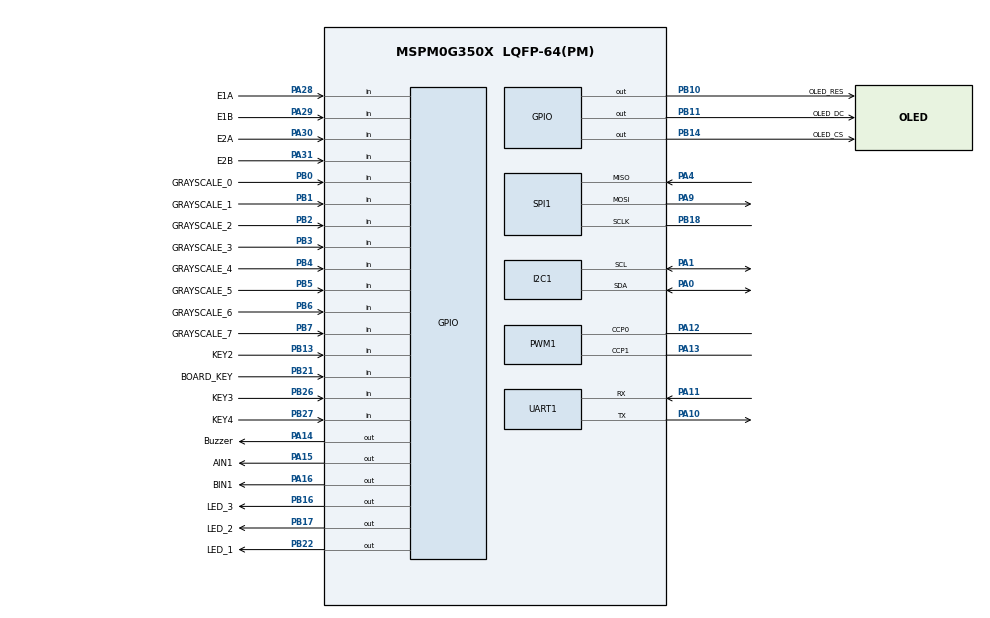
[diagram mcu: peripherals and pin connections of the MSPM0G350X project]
/**
 * @cliArgs --device "MSPM0G350X" --part "Default" --package "LQFP-64(PM)" --product "mspm0_sdk@2.10.00.04"
 * @versions {"tool":"1.26.2+4477"}
 */

/**
 * Import the modules used in this configuration.
 */
const GPIO    = scripting.addModule("/ti/driverlib/GPIO", {}, false);
const GPIO1   = GPIO.addInstance();
const GPIO2   = GPIO.addInstance();
const GPIO3   = GPIO.addInstance();
const GPIO4   = GPIO.addInstance();
const GPIO5   = GPIO.addInstance();
const GPIO6   = GPIO.addInstance();
const GPIO7   = GPIO.addInstance();
const I2C     = scripting.addModule("/ti/driverlib/I2C", {}, false);
const I2C1    = I2C.addInstance();
const PWM     = scripting.addModule("/ti/driverlib/PWM", {}, false);
const PWM1    = PWM.addInstance();
const SPI     = scripting.addModule("/ti/driverlib/SPI", {}, false);
const SPI1    = SPI.addInstance();
const SYSCTL  = scripting.addModule("/ti/driverlib/SYSCTL");
const SYSTICK = scripting.addModule("/ti/driverlib/SYSTICK");
const TIMER   = scripting.addModule("/ti/driverlib/TIMER", {}, false);
const TIMER1  = TIMER.addInstance();
const TIMER2  = TIMER.addInstance();
const UART    = scripting.addModule("/ti/driverlib/UART", {}, false);
const UART1   = UART.addInstance();
const UART2   = UART.addInstance();
const UART3   = UART.addInstance();

/**
 * Write custom configuration values to the imported modules.
 */
const gate7  = system.clockTree["MFCLKGATE"];
gate7.enable = true;

GPIO1.port                          = "PORTB";
GPIO1.$name                         = "LED";
GPIO1.associatedPins.create(3);
GPIO1.associatedPins[0].assignedPin = "22";
GPIO1.associatedPins[0].$name       = "LED_1";
GPIO1.associatedPins[0].pin.$assign = "PB22";
GPIO1.associatedPins[1].$name       = "LED_2";
GPIO1.associatedPins[1].pin.$assign = "PB17";
GPIO1.associatedPins[2].$name       = "LED_3";
GPIO1.associatedPins[2].pin.$assign = "PB16";

const Board = scripting.addModule("/ti/driverlib/Board", {}, false);

GPIO2.port                          = "PORTB";
GPIO2.$name                         = "SPI_OLED";
GPIO2.associatedPins.create(3);
GPIO2.associatedPins[0].assignedPin = "10";
GPIO2.associatedPins[0].ioStructure = "SD";
GPIO2.associatedPins[0].$name       = "OLED_RES";
GPIO2.associatedPins[0].pin.$assign = "PB10";
GPIO2.associatedPins[1].ioStructure = "SD";
GPIO2.associatedPins[1].assignedPin = "11";
GPIO2.associatedPins[1].$name       = "OLED_DC";
GPIO2.associatedPins[1].pin.$assign = "PB11";
GPIO2.associatedPins[2].assignedPin = "14";
GPIO2.associatedPins[2].ioStructure = "SD";
GPIO2.associatedPins[2].$name       = "OLED_CS";
GPIO2.associatedPins[2].pin.$assign = "PB14";

GPIO3.$name                              = "KEY_GROIP";
GPIO3.associatedPins.create(5);
GPIO3.associatedPins[0].$name            = "BOARD_KEY";
GPIO3.associatedPins[0].direction        = "INPUT";
GPIO3.associatedPins[0].assignedPort     = "PORTB";
GPIO3.associatedPins[0].assignedPin      = "21";
GPIO3.associatedPins[0].internalResistor = "PULL_UP";
GPIO3.associatedPins[0].pin.$assign      = "PB21";
GPIO3.associatedPins[1].$name            = "KEY1";
GPIO3.associatedPins[1].direction        = "INPUT";
GPIO3.associatedPins[1].internalResistor = "PULL_UP";
GPIO3.associatedPins[2].$name            = "KEY2";
GPIO3.associatedPins[2].direction        = "INPUT";
GPIO3.associatedPins[2].internalResistor = "PULL_UP";
GPIO3.associatedPins[2].pin.$assign      = "PB13";
GPIO3.associatedPins[3].$name            = "KEY3";
GPIO3.associatedPins[3].direction        = "INPUT";
GPIO3.associatedPins[3].internalResistor = "PULL_UP";
GPIO3.associatedPins[3].pin.$assign      = "PB26";
GPIO3.associatedPins[4].$name            = "KEY4";
GPIO3.associatedPins[4].direction        = "INPUT";
GPIO3.associatedPins[4].internalResistor = "PULL_UP";
GPIO3.associatedPins[4].pin.$assign      = "PB27";

GPIO4.port                                = "PORTA";
GPIO4.$name                               = "ENCODER";
GPIO4.associatedPins.create(4);
GPIO4.associatedPins[0].$name             = "E1A";
GPIO4.associatedPins[0].direction         = "INPUT";
GPIO4.associatedPins[0].assignedPin       = "28";
GPIO4.associatedPins[0].interruptEn       = true;
GPIO4.associatedPins[0].inputFilter       = "8_CYCLES";
GPIO4.associatedPins[0].internalResistor  = "PULL_DOWN";
GPIO4.associatedPins[0].polarity          = "RISE_FALL";
GPIO4.associatedPins[0].interruptPriority = "0";
GPIO4.associatedPins[0].pin.$assign       = "PA28";
GPIO4.associatedPins[1].$name             = "E1B";
GPIO4.associatedPins[1].direction         = "INPUT";
GPIO4.associatedPins[1].assignedPin       = "29";
GPIO4.associatedPins[1].interruptEn       = true;
GPIO4.associatedPins[1].internalResistor  = "PULL_DOWN";
GPIO4.associatedPins[1].inputFilter       = "8_CYCLES";
GPIO4.associatedPins[1].polarity          = "RISE_FALL";
GPIO4.associatedPins[1].interruptPriority = "0";
GPIO4.associatedPins[1].pin.$assign       = "PA29";
GPIO4.associatedPins[2].$name             = "E2A";
GPIO4.associatedPins[2].direction         = "INPUT";
GPIO4.associatedPins[2].assignedPin       = "30";
GPIO4.associatedPins[2].interruptEn       = true;
GPIO4.associatedPins[2].internalResistor  = "PULL_DOWN";
GPIO4.associatedPins[2].inputFilter       = "8_CYCLES";
GPIO4.associatedPins[2].polarity          = "RISE_FALL";
GPIO4.associatedPins[2].interruptPriority = "0";
GPIO4.associatedPins[2].pin.$assign       = "PA30";
GPIO4.associatedPins[3].$name             = "E2B";
GPIO4.associatedPins[3].direction         = "INPUT";
GPIO4.associatedPins[3].assignedPin       = "31";
GPIO4.associatedPins[3].interruptEn       = true;
GPIO4.associatedPins[3].internalResistor  = "PULL_DOWN";
GPIO4.associatedPins[3].inputFilter       = "8_CYCLES";
GPIO4.associatedPins[3].polarity          = "RISE_FALL";
GPIO4.associatedPins[3].interruptPriority = "0";
GPIO4.associatedPins[3].pin.$assign       = "PA31";

GPIO5.$name                         = "A4950";
GPIO5.associatedPins.create(2);
GPIO5.associatedPins[0].$name       = "AIN1";
GPIO5.associatedPins[0].pin.$assign = "PA15";
GPIO5.associatedPins[1].$name       = "BIN1";
GPIO5.associatedPins[1].pin.$assign = "PA16";

GPIO6.$name                         = "GRAYSCALE";
GPIO6.associatedPins.create(8);
GPIO6.associatedPins[0].$name       = "GRAYSCALE_0";
GPIO6.associatedPins[0].direction   = "INPUT";
GPIO6.associatedPins[0].pin.$assign = "PB0";
GPIO6.associatedPins[1].$name       = "GRAYSCALE_1";
GPIO6.associatedPins[1].direction   = "INPUT";
GPIO6.associatedPins[1].pin.$assign = "PB1";
GPIO6.associatedPins[2].$name       = "GRAYSCALE_2";
GPIO6.associatedPins[2].direction   = "INPUT";
GPIO6.associatedPins[2].pin.$assign = "PB2";
GPIO6.associatedPins[3].$name       = "GRAYSCALE_3";
GPIO6.associatedPins[3].direction   = "INPUT";
GPIO6.associatedPins[3].pin.$assign = "PB3";
GPIO6.associatedPins[4].$name       = "GRAYSCALE_4";
GPIO6.associatedPins[4].direction   = "INPUT";
GPIO6.associatedPins[4].pin.$assign = "PB4";
GPIO6.associatedPins[5].$name       = "GRAYSCALE_5";
GPIO6.associatedPins[5].direction   = "INPUT";
GPIO6.associatedPins[5].pin.$assign = "PB5";
GPIO6.associatedPins[6].$name       = "GRAYSCALE_6";
GPIO6.associatedPins[6].direction   = "INPUT";
GPIO6.associatedPins[6].pin.$assign = "PB6";
GPIO6.associatedPins[7].$name       = "GRAYSCALE_7";
GPIO6.associatedPins[7].direction   = "INPUT";
GPIO6.associatedPins[7].pin.$assign = "PB7";

GPIO7.$name                         = "BUZZER";
GPIO7.associatedPins[0].$name       = "Buzzer";
GPIO7.associatedPins[0].pin.$assign = "PA14";

I2C1.$name                             = "I2C_6050";
I2C1.basicEnableController             = true;
I2C1.basicControllerStandardBusSpeed   = "Fast";
I2C1.peripheral.$assign                = "I2C0";
I2C1.peripheral.sdaPin.$assign         = "PA0";
I2C1.peripheral.sclPin.$assign         = "PA1";
I2C1.sdaPinConfig.hideOutputInversion  = scripting.forceWrite(false);
I2C1.sdaPinConfig.onlyInternalResistor = scripting.forceWrite(false);
I2C1.sdaPinConfig.passedPeripheralType = scripting.forceWrite("Digital");
I2C1.sdaPinConfig.$name                = "ti_driverlib_gpio_GPIOPinGeneric5";
I2C1.sclPinConfig.hideOutputInversion  = scripting.forceWrite(false);
I2C1.sclPinConfig.onlyInternalResistor = scripting.forceWrite(false);
I2C1.sclPinConfig.passedPeripheralType = scripting.forceWrite("Digital");
I2C1.sclPinConfig.$name                = "ti_driverlib_gpio_GPIOPinGeneric6";

PWM1.$name                      = "PWM_0";
PWM1.clockDivider               = 8;
PWM1.timerStartTimer            = true;
PWM1.timerCount                 = 10000;
PWM1.peripheral.ccp0Pin.$assign = "PA12";
PWM1.peripheral.ccp1Pin.$assign = "PA13";
PWM1.PWM_CHANNEL_0.$name        = "ti_driverlib_pwm_PWMTimerCC0";
PWM1.PWM_CHANNEL_0.initVal      = "HIGH";
PWM1.PWM_CHANNEL_0.invert       = true;
PWM1.PWM_CHANNEL_1.$name        = "ti_driverlib_pwm_PWMTimerCC1";
PWM1.PWM_CHANNEL_1.initVal      = "HIGH";
PWM1.PWM_CHANNEL_1.invert       = true;
PWM1.ccp0PinConfig.$name        = "ti_driverlib_gpio_GPIOPinGeneric7";
PWM1.ccp1PinConfig.$name        = "ti_driverlib_gpio_GPIOPinGeneric8";

SPI1.$name                              = "SPI";
SPI1.frameFormat                        = "MOTO3";
SPI1.sclkPinConfig.direction            = scripting.forceWrite("OUTPUT");
SPI1.sclkPinConfig.onlyInternalResistor = scripting.forceWrite(false);
SPI1.sclkPinConfig.passedPeripheralType = scripting.forceWrite("Digital");
SPI1.sclkPinConfig.$name                = "ti_driverlib_gpio_GPIOPinGeneric2";
SPI1.mosiPinConfig.direction            = scripting.forceWrite("OUTPUT");
SPI1.mosiPinConfig.hideOutputInversion  = scripting.forceWrite(false);
SPI1.mosiPinConfig.onlyInternalResistor = scripting.forceWrite(false);
SPI1.mosiPinConfig.passedPeripheralType = scripting.forceWrite("Digital");
SPI1.mosiPinConfig.$name                = "ti_driverlib_gpio_GPIOPinGeneric3";
SPI1.misoPinConfig.onlyInternalResistor = scripting.forceWrite(false);
SPI1.misoPinConfig.passedPeripheralType = scripting.forceWrite("Digital");
SPI1.misoPinConfig.$name                = "ti_driverlib_gpio_GPIOPinGeneric4";
SPI1.peripheral.sclkPin.$assign         = "PB18";
SPI1.peripheral.mosiPin.$assign         = "PA9";
SPI1.peripheral.misoPin.$assign         = "PA4";

SYSCTL.forceDefaultClkConfig = true;
SYSCTL.clockTreeEn           = true;

SYSTICK.periodEnable      = true;
SYSTICK.period            = 32000;
SYSTICK.interruptEnable   = true;
SYSTICK.systickEnable     = true;
SYSTICK.interruptPriority = "3";

TIMER1.$name              = "TIMER_0";
TIMER1.timerClkPrescale   = 100;
TIMER1.timerMode          = "PERIODIC";
TIMER1.timerClkDiv        = 8;
TIMER1.timerStartTimer    = true;
TIMER1.interrupts         = ["ZERO"];
TIMER1.timerPeriod        = "1ms";
TIMER1.peripheral.$assign = "TIMA0";

TIMER2.$name            = "TIMER_1";
TIMER2.timerClkDiv      = 8;
TIMER2.timerStartTimer  = true;
TIMER2.timerClkPrescale = 100;
TIMER2.timerMode        = "PERIODIC";
TIMER2.timerPeriod      = "20 ms";

UART1.$name                    = "UART_0";
UART1.targetBaudRate           = 115200;
UART1.uartClkSrc               = "MFCLK";
UART1.enabledInterrupts        = ["RX"];
UART1.peripheral.$assign       = "UART0";
UART1.peripheral.rxPin.$assign = "PA11";
UART1.peripheral.txPin.$assign = "PA10";
UART1.txPinConfig.$name        = "ti_driverlib_gpio_GPIOPinGeneric0";
UART1.rxPinConfig.$name        = "ti_driverlib_gpio_GPIOPinGeneric1";

UART2.$name             = "UART_1";
UART2.targetBaudRate    = 115200;
UART2.txPinConfig.$name = "ti_driverlib_gpio_GPIOPinGeneric11";
UART2.rxPinConfig.$name = "ti_driverlib_gpio_GPIOPinGeneric12";

UART3.$name             = "UART_2";
UART3.targetBaudRate    = 115200;
UART3.txPinConfig.$name = "ti_driverlib_gpio_GPIOPinGeneric13";
UART3.rxPinConfig.$name = "ti_driverlib_gpio_GPIOPinGeneric14";

/**
 * Pinmux solution for unlocked pins/peripherals. This ensures that minor changes to the automatic solver in a future
 * version of the tool will not impact the pinmux you originally saw.  These lines can be completely deleted in order to
 * re-solve from scratch.
 */
Board.peripheral.$suggestSolution            = "DEBUGSS";
Board.peripheral.swclkPin.$suggestSolution   = "PA20";
Board.peripheral.swdioPin.$suggestSolution   = "PA19";
GPIO3.associatedPins[1].pin.$suggestSolution = "PB15";
PWM1.peripheral.$suggestSolution             = "TIMG0";
SPI1.peripheral.$suggestSolution             = "SPI0";
TIMER2.peripheral.$suggestSolution           = "TIMA1";
UART2.peripheral.$suggestSolution            = "UART2";
UART2.peripheral.rxPin.$suggestSolution      = "PA22";
UART2.peripheral.txPin.$suggestSolution      = "PA21";
UART3.peripheral.$suggestSolution            = "UART1";
UART3.peripheral.rxPin.$suggestSolution      = "PA18";
UART3.peripheral.txPin.$suggestSolution      = "PA17";
